# R7KA8M2AD register map
Vendor: Renesas Electronics Corporation; Series: RA8; File version: 1.10.02
CPU: CM85 r0p2, little endian, MPU, FPU, VTOR, 4 interrupt priority bits, 96 interrupts
Registers are 32-bit, read-write, reset 0x0 unless marked. A register's access mark holds for its fields unless they carry their own. Offsets are from the block's base; [hi:lo] are bit positions; {n}, {i} and the like mark numbered series; 'fields as' and 'values as' point back to an identical list.

## GWCA0 — Gateway CPU Agent
Base 0x403CE000
Same registers: GWCA0_NS 0x503CE000
0x00 GWMC reset 0x1 — Mode Configuration Register
  [1:0] OPC — Operating Mode Command
    0=Enter RESET mode; 1=Enter DISABLE mode; 2=Enter CONFIG mode; 3=Enter OPERATION mode
0x04 GWMS ro reset 0x1 — Mode Status Register
  [1:0] OPS — Operating Mode Status
    0=RESET mode; 1=DISABLE mode; 2=CONFIG mode; 3=OPERATION mode
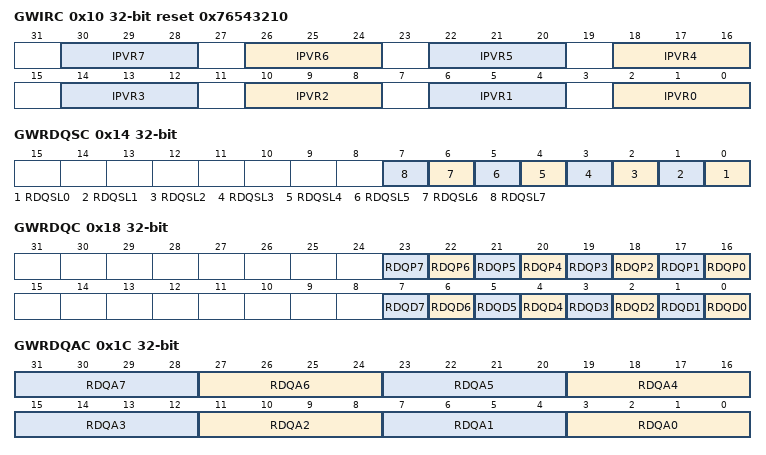
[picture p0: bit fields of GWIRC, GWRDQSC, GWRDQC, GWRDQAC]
0x10 GWIRC reset 0x76543210 — IPV Remapping Configuration Register [802.1Q]
  [4n+2:4n] IPVR{n} (n=0..7) — IPV remapping {n}
0x14 GWRDQSC — RX Descriptor Queue Security Configuration Register
  [all] fields
    0=Queue i unsecure; 1=Queue i secure
  [n] RDQSL{n} (n=0..7) — RX Descriptor Queue i Security Level (The variable i corresponds to the bit number.)
0x18 GWRDQC — RX Descriptor Queue Control Register
  [n+16] RDQP{n} (n=0..7) — RX Descriptor Queue i Pause (The variable i corresponds to the bit position number.)
    0=Queue i active; 1=Queue i paused
  [n] RDQD{n} (n=0..7) — RX Descriptor Queue i Disable (The variable i corresponds to the bit position number.)
    0=Queue i enabled; 1=Queue i disabled
0x1C GWRDQAC — RX Descriptor Queue Arbitration Control Register
  [all] fields
    0=Queue i strict arbitration; other=Others (Queue i WRR arbitration)
  [4n+3:4n] RDQA{n} (n=0..7) — RX Descriptor Queue {n} Arbitration
0x20 GWRGC — RX General Configuration Register
  [0] RCPT — Receive CRC Pass Through [802.3]
    0=FCS is not passed to GWCPU. If a descriptor is received from forwarding engine with FDESCR.FI equal to 1, GWCA remove the last 4 bytes of the Frame Data (FCS).; 1=FCS is passed to GWCPU GWCA don’t remove FCS from the Frame which has one (a descriptor is received from forwarding engine with FDESCR.FI equal to 1) if the frame has not been modified by the switch (No update due to VLAN tagging/untagging and no update requested by L3 routing [FWD])
{0x40+4i} GWRMFSC{i} (i=0..7) reset 0xFFFF — Reception Maximum Frame Size Configuration Register {i}
  [15:0] MFS — Maximum Frame Size
{0x60+4i} GWRDQDC{i} (i=0..7) — Reception Descriptor Queue {i} Depth Configuration Register
  [9:0] DQD — Descriptor Queue Depth
{0x80+4i} GWRDQM{i} (i=0..7) ro — RX Descriptor Queue {i} Monitoring Register
  [9:0] DNQ — Descriptor Number in Queue
{0xA0+4i} GWRDQMLM{i} (i=0..7) ro — RX Descriptor Queue {i} Max Level Monitoring Register
  [9:0] DMLQ — Descriptor Max Level in Queue
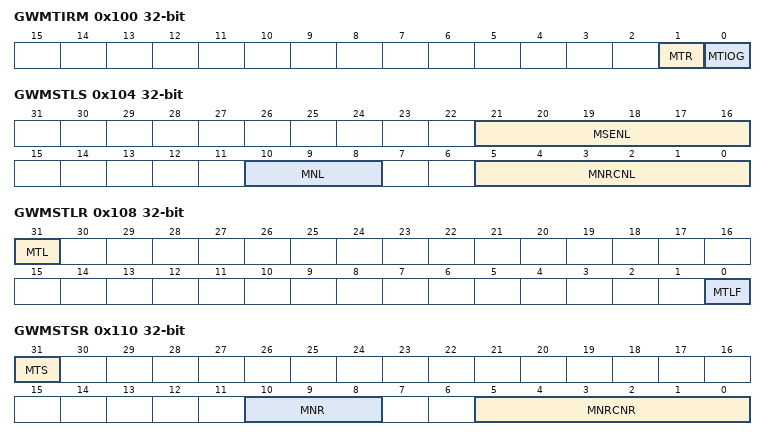
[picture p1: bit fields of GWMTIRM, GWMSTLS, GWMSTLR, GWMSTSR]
0x100 GWMTIRM — Multicast Table Initialization Register Monitoring Register
  [1] MTR ro — Multicast Table Ready
  [0] MTIOG — Multicast Table Initialization Ongoing
0x104 GWMSTLS — Multicast Table Learning Setting Register
  [21:16] MSENL — Multicast Setting Entry Number Learn
  [10:8] MNL — Multicast Number Learn
  [5:0] MNRCNL — Multicast Next Descriptor Chain Number Learn
0x108 GWMSTLR ro — Multicast Table Learning Result Register
  [31] MTL — Multicast Table Learning
  [0] MTLF — Multicast Table Learning Fail
    0=Entry learning did not fail because the Multicast table is not ready; 1=Entry learning failed the Multicast table is not ready
0x10C GWMSTSS — Multicast Table Searching Setting Register
  [5:0] MSENS — Multicast Setting Entry Number Search
0x110 GWMSTSR ro — Multicast Table Searching Result Register
  [31] MTS — Multicast Table Searching
  [10:8] MNR — Multicast Number Result
  [5:0] MNRCNR — Multicast Next RX Descriptor Chain Number Result
0x120 GWMAC0 — MAC Address Configuration Register 0
  [15:0] MAU — MAC Address Upper Part
0x124 GWMAC1 — MAC Address Configuration Register 1
  [31:0] MAL — MAC Address Lower Part
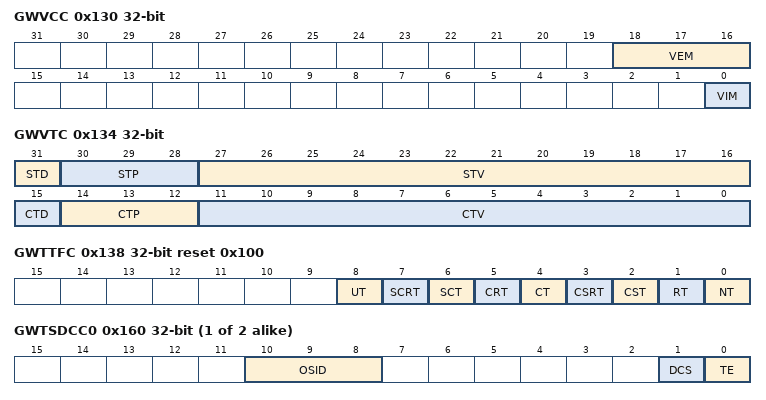
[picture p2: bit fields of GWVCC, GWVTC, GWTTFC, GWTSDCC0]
0x130 GWVCC — VLAN Control Configuration Register
  [18:16] VEM — VLAN Egress Mode
    0=No VLAN mode, frames are transmitted with no VLAN; 1=C-TAG VLAN mode, frames are transmitted with ingress C-TAG if there is one stored in the Local RAM; 2=HW C-TAG VLAN mode, frames are transmitted with the C-TAG stored in local RAM; 3=SC-TAG VLAN mode, frames are transmitted with ingress C-TAG and S-TAG if they were stored in the Local RAM; 4=HW SC-TAG VLAN mode, frames are transmitted with the C-TAG and S-TAG stored in local RAM
  [0] VIM — VLAN Ingress Mode
    0=Incoming VLAN mode; 1=Port based VLAN mode
0x134 GWVTC — VLAN TAG Configuration Register
  [31] STD — S-TAG DEI
  [30:28] STP — S-TAG PCP
  [27:16] STV — S-TAG VLAN
  [15] CTD — C-TAG DEI
  [14:12] CTP — C-TAG PCP
  [11:0] CTV — C-TAG VLAN
0x138 GWTTFC reset 0x100 — Transmission TAG Filtering Configuration Register
  [8] UT — Unknown TAG
    0=Unknown Tag frame passed; 1=Unknown Tag frame rejected
  [7] SCRT — SCR-TAG
    0=SCR-TAG frame passed; 1=SCR-TAG frame rejected
  [6] SCT — SC-TAG
    0=SC-TAG frame passed; 1=SC-TAG frame rejected
  [5] CRT — CR-TAG
    0=CR-TAG frame passed; 1=CR-TAG frame rejected
  [4] CT — C-TAG
    0=C-TAG frame passed; 1=C-TAG frame rejected
  [3] CSRT — CoSR-TAG
    0=CoSR-TAG frame passed; 1=CoSR-TAG frame rejected
  [2] CST — CoS-TAG
    0=CoS-TAG frame passed; 1=CoS-TAG frame rejected
  [1] RT — R-TAG
    0=R-TAG frame passed; 1=R-TAG frame rejected
  [0] NT — No Tag
    0=No Tag frame passed; 1=No Tag frame rejected
{0x140+8i} GWTDCAC{i}0 (i=0..1) — Timestamp Descriptor Chain {i} Address Configuration Register 0
  [7:0] TSCCAU — TS Descriptor Chain s Current Address Upper Part
{0x144+8i} GWTDCAC{i}1 (i=0..1) — Timestamp Descriptor Chain {i} Address Configuration Register 1
  [31:0] TSCCAL — TS Descriptor Chain s Current Address Lower Part
{0x160+4i} GWTSDCC{i} (i=0..1) — Timestamp Descriptor Chain {i} Configuration Register
  [10:8] OSID
  [1] DCS — Descriptor Chain Select
  [0] TE — Timer Enable
0x180 GWTSNM ro — Timestamp Number Monitoring Register
  [4:0] TNTR — Timestamp Number in Timestamp RAM
0x184 GWTSMNM ro — Timestamp Maximum Number Monitoring Register
  [4:0] TMNTR — Timestamp Maximum Number in Timestamp RAM
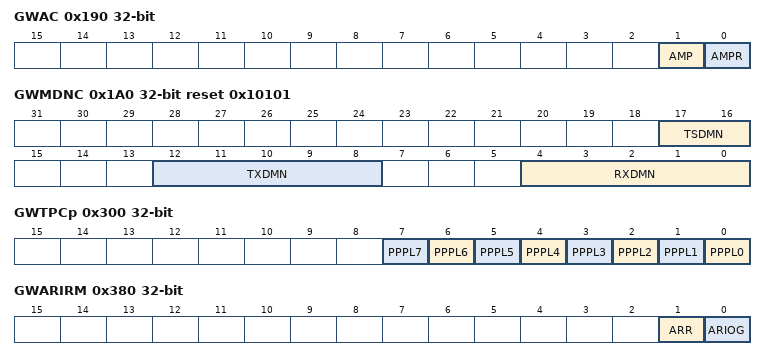
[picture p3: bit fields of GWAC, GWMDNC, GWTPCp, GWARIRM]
0x190 GWAC — AXI Control Register
  [1] AMP — AXI Master Paused
    0=AXI master not paused (transaction ongoing); 1=AXI master paused (no transaction ongoing)
  [0] AMPR — AXI Master Pause Request
    0=AXI master pause not requested; 1=AXI master pause requested
0x194 GWDCBAC0 — Descriptor Chain Base Address Configuration Register 0
  [7:0] DCBAU — Descriptor Chain Base Address Upper Part
0x198 GWDCBAC1 — Descriptor Chain Base Address Configuration Register 1
  [31:0] DCBAL — Descriptor Chain Base Address Lower Part
0x1A0 GWMDNC reset 0x10101 — Maximum Descriptor Number Configuration Register
  [17:16] TSDMN — Timestamp Descriptor Maximum Number
  [12:8] TXDMN — TX Descriptor Maximum Number
  [4:0] RXDMN — RX Descriptor Maximum Number
0x200 GWTRC0 — Transmission Request Configuration Register
0x204 GWTRC1 — Transmission Request Configuration Register
0x300 GWTPCp — Transmission Pause Configuration Register p (p = 0 to 1)
  [all] fields
    0=Transmission queues with their priority GWDCCi.DCP set to i are not paused when pause level p is set (PAUSE[2][p] is set [COMA]); 1=Transmission queues with the priority GWDCCi.DCP set to i are paused when pause level p is set (PAUSE[2][p] is set [COMA])
  [n] PPPL{n} (n=0..7) — Per Priority Pause Level i (The variable i corresponds to the bit position number.)
0x380 GWARIRM — AXI RAM Initialization Register Monitoring Register
  [1] ARR ro — AXI RAM Ready
  [0] ARIOG — AXI RAM Initialization Ongoing
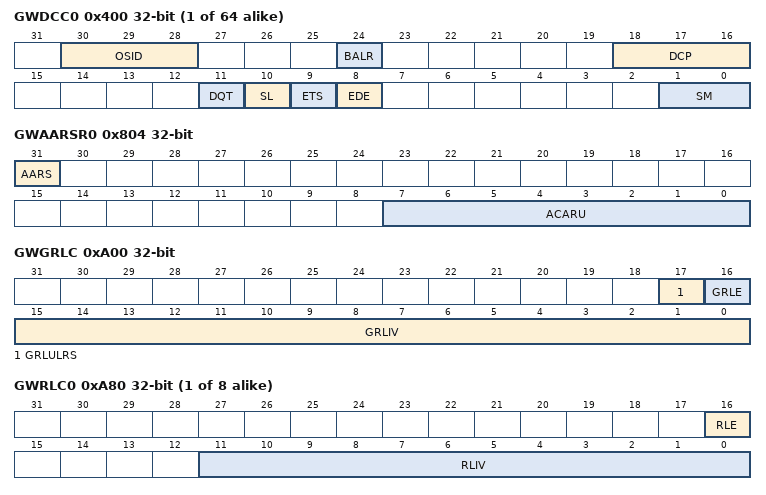
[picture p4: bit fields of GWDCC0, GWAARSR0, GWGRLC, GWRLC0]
{0x400+4i} GWDCC{i} (i=0..63) — Descriptor Chain {i} Configuration Register
  [30:28] OSID
  [24] BALR — Base Address Load Request
  [18:16] DCP — Descriptor Chain Priority
    0=Lowest priority; 7=Highest priority
  [11] DQT — Descriptor Queue Type
    0=Descriptor queue i is a reception queue; 1=Descriptor queue i is a transmission queue
  [10] SL — Security Level
    0=Chain i unsecure; 1=Chain i secure
  [9] ETS — Enable Timestamp Storage
    0=Timestamp is not added in the Descriptor; 1=Timestamp is added in the Descriptor
  [8] EDE — Extended Descriptor Enable
    0=Basic Descriptor; 1=Extended Descriptor
  [1:0] SM — Synchronization Mode
    0=Normal mode (full descriptor write back); 1=No-write-back mode (no descriptor write back); 2=Keep-DT mode (no update of DT field at descriptor write back)
0x800 GWAARSS — AXI Address RAM Searching Setting Register
  [5:0] AARA — AXI Address RAM Address
0x804 GWAARSR0 ro — AXI Address RAM Searching Result Register 0
  [31] AARS — AXI Address RAM Searching
  [7:0] ACARU — AXI Current Address Result Upper Part
0x808 GWAARSR1 ro — AXI Address RAM Searching Result Register 1
  [31:0] ACARL — AXI Current Address Result Lower Part
{0x840+4i} GWIDAUAS{i} (i=0..3) — Incremental Data Area {i} Used Area Size Register
  [23:0] IDAUAS — Incremental Data Area Used Size of RX Descriptor Chain i
{0x880+4i} GWIDASM{i} (i=0..3) ro — Incremental Data Area {i} Size Monitoring Register
  [23:0] IDAS — Incremental Data Area Size of RX Descriptor Chain i
{0x900+8i} GWIDASAM{i}0 (i=0..3) ro — Incremental Data Area {i} Start Address Monitoring Register 0
  [7:0] IDASAU — Incremental Data Area Start Address Upper Part of RX Descriptor Chain i
{0x904+8i} GWIDASAM{i}1 (i=0..3) ro — Incremental Data Area {i} Start Address Monitoring Register 1
  [31:0] IDASAL — Incremental Data Area Start Address Lower Part of RX Descriptor Chain i
{0x980+8i} GWIDACAM{i}0 (i=0..3) ro — Incremental Data Area {i} Current Address Monitoring Register 0
  [7:0] IDACAU — Incremental Data Area Current Address Upper Part of RX Descriptor Chain i
{0x984+8i} GWIDACAM{i}1 (i=0..3) ro — Incremental Data Area {i} Current Address Monitoring Register 1
  [31:0] IDACAL — Incremental Data Area Current Address Lower Part of RX Descriptor Chain i
0xA00 GWGRLC — Global Rate Limiter Configuration Register
  [17] GRLULRS — Global Rate Limiter Upper Limit Reached Status Flag
  [16] GRLE — Global Rate Limiter Enable
    0=Global Rate limiter disabled; 1=Global Rate limiter enabled
  [15:0] GRLIV — Global Rate Limiter Incremental Value
0xA04 GWGRLULC — Global Rate Limiter Upper Limit Configuration Register
  [23:0] GRLUL — Global Rate Limiter Upper Limit
{0xA80+8i} GWRLC{i} (i=0..7) — Rate Limiter {i} Configuration Register
  [16] RLE — Rate Limiter Enable
    0=Rate limiter i disabled; 1=Rate limiter i enabled
  [11:0] RLIV — Rate Limiter Incremental Value
{0xA84+8i} GWRLULC{i} (i=0..7) — Rate Limiter {i} Upper Limit Configuration Register
  [23:0] RLUL — Rate Limiter Upper Limit
0xB80 GWIDPC — Interrupt Delay Prescaler Configuration Register
  [9:0] IDPV — Interrupt Delay Prescaler Value
0x1000 GWRDCN ro — Received Data Counter Register
  [31:0] RDN — Received Data Number
0x1004 GWTDCN ro — Transmitted Data Counter Register
  [31:0] TDN — Transmitted Data Number
0x1008 GWTSCN ro — Timestamp Counter Register
  [31:0] TN — Timestamp Number
0x100C GWTSOVFECN ro — Timestamp Overflow Error Counter Register
  [15:0] TSOVFEN — Timestamp Overflow Error Number
0x1010 GWUSMFSECN ro — Under Minimum Frame Size Error Counter Register
  [15:0] USMFSEN — Under Switch Minimum Frame Size Error Number
0x1014 GWTFECN ro — TAG Filtering Error Counter Register
  [15:0] TFEN — TAG Filtering Error Number
0x1018 GWSEQECN ro — Sequence Error Counter Register
  [15:0] SEQEN — Sequence Error Number
0x1020 GWTXDNECN ro — TX Descriptor Number Error Counter Register
  [15:0] TXDNEN — TX Descriptor Number Error Number
0x1024 GWFSECN ro — Frame Size Error Counter Register
  [15:0] FSEN — Frame Size Error Number
0x1028 GWTDFECN ro — Timestamp Descriptor Full Error Counter Register
  [15:0] TDFEN — Timestamp Descriptor Full Error Number
0x102C GWTSDNECN ro — Timestamp Descriptor Number Error Counter Register
  [15:0] TSDNEN — Timestamp Descriptor Number Error Number
0x1030 GWDQOECN ro — Descriptor Queue Overflow Error Counter Register
  [15:0] DQOEN — Descriptor Queue Overflow Error Number
0x1034 GWDQSECN ro — Descriptor Queue Security Error Counter Register
  [15:0] DQSEN — Descriptor Queue Security Error Number
0x1038 GWDFECN ro — Descriptor Full Error Counter Register
  [15:0] DFEN — Descriptor Full Error Number
0x103C GWDSECN ro — Descriptor Security Error Counter Register
  [15:0] DSEN — Descriptor Security Error Number
0x1040 GWDSZECN ro — Data Size Error Counter Register
  [15:0] DSZEN — Data Size Error Number
0x1044 GWDCTECN ro — Descriptor Chain Type Error Counter Register
  [15:0] DCTEN — Descriptor Chain Type Error Number
0x1048 GWRXDNECN ro — RX Descriptor Number Error Counter Register
  [15:0] RXDNEN — RX Descriptor Number Error Number
0x1100 GWDIS0 — Data Interrupt Status Register
0x1104 GWDIE0 — Data Interrupt Enable Register
0x1108 GWDID0 — Data Interrupt Disable Register
0x110C GWDIDS0 — Data Interrupt Delayed Status Register
0x1110 GWDIS1 — Data Interrupt Status Register
0x1114 GWDIE1 — Data Interrupt Enable Register
0x1118 GWDID1 — Data Interrupt Disable Register
0x111C GWDIDS1 — Data Interrupt Delayed Status Register
0x1180 GWTSDIS — Timestamp Data Interrupt Status Register
  [1:0] TSDIS1 to TSDIS0 — Timestamp Data i Interrupt Status Flag
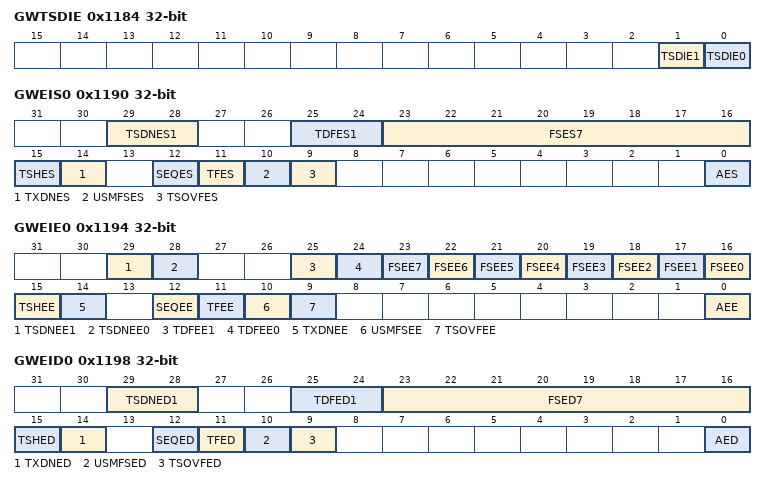
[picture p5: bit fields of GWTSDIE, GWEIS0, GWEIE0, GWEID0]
0x1184 GWTSDIE — Timestamp Data Interrupt Enable Register
  [1] TSDIE1 — Timestamp Data i Interrupt Enable
    0=Interrupt disabled; 1=Interrupt Enabled
  [0] TSDIE0 — Timestamp Data i Interrupt Enable
    0=Interrupt disabled; 1=Interrupt Enabled
0x1188 GWTSDID ro — Timestamp Data Interrupt Disable Register
  [1:0] TSDID1 to TSDID0 — Timestamp Data i Interrupt Disable
0x1190 GWEIS0 — Error Interrupt Status Register 0
  [29:28] TSDNES1 to TSDNES0 — Timestamp Descriptor i Number Error Status Flag
  [25:24] TDFES1 to TDFES0 — Timestamp Descriptor i Full Error Status Flag
  [23:16] FSES7 to FSES0 — Frame Size Error Status Flag i
  [15] TSHES — Timestamp Hardware Error Status Flag
  [14] TXDNES — TX Descriptor Number Error Status Flag
  [12] SEQES — Sequence Error Status Flag
  [11] TFES — TAG Filtering Error Status Flag
  [10] USMFSES — Under Switch Minimum Frame Size Error Status Flag
  [9] TSOVFES — Timestamp Overflow Error Status Flag
  [0] AES — AXI Error Status Flag
0x1194 GWEIE0 — Error Interrupt Enable Register 0
  [29] TSDNEE1 — Timestamp Descriptor i Number Error Enable
    0=Interrupt disabled; 1=Interrupt enabled
  [28] TSDNEE0 — Timestamp Descriptor i Number Error Enable
    0=Interrupt disabled; 1=Interrupt enabled
  [25] TDFEE1 — Timestamp Descriptor i Full Error Enable
    0=Interrupt disabled for descriptor queue i; 1=Interrupt enabled for descriptor queue i
  [24] TDFEE0 — Timestamp Descriptor i Full Error Enable
    values as TDFEE1
  [n+16] FSEE{n} (n=0..7) — Frame Size Error Enable i (The variable i corresponds to the bit position number.)
    0=Interrupt disabled for error q; 1=Interrupt enabled for error q
  [15] TSHEE — Timestamp Hardware Error Enable
    0=Interrupt disabled; 1=Interrupt Enabled
  [14] TXDNEE — TX Descriptor Number Error Enable
    0=Interrupt disabled; 1=Interrupt Enabled
  [12] SEQEE — Sequence Error Enable
    0=Interrupt disabled; 1=Interrupt Enabled
  [11] TFEE — TAG Filtering Error Enable
    0=Interrupt disabled; 1=Interrupt Enabled
  [10] USMFSEE — Under Minimum Frame Size Error Enable
    0=Interrupt disabled; 1=Interrupt Enabled
  [9] TSOVFEE — Timestamp Overflow Error Enable
    0=Interrupt disabled; 1=Interrupt Enabled
  [0] AEE — AXI Error Enable
    0=Interrupt disabled; 1=Interrupt Enabled
0x1198 GWEID0 ro — Error Interrupt Disable Register 0
  [29:28] TSDNED1 to TSDNED0 — Timestamp Descriptor i Number Error Disable
  [25:24] TDFED1 to TDFED0 — Timestamp Descriptor i Full Error Disable
  [23:16] FSED7 to FSED0 — Frame Size Error Disable i
  [15] TSHED — Timestamp Hardware Full Error Disable
  [14] TXDNED — TX Descriptor Number Error Disable
  [12] SEQED — Sequence Error Disable
  [11] TFED — TAG Filtering Error Disable
  [10] USMFSED — Under Minimum Frame Size Error Disable
  [9] TSOVFED — Timestamp Overflow Error Disable
  [0] AED — AXI Error Disable
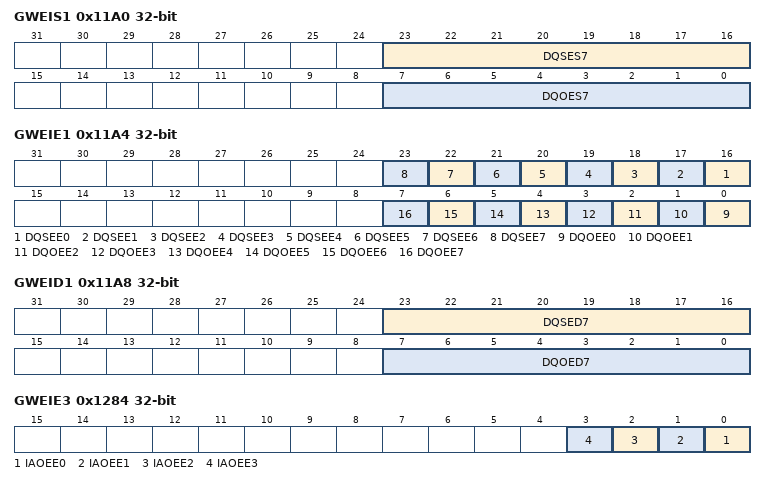
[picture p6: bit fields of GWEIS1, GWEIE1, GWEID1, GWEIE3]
0x11A0 GWEIS1 — Error Interrupt Status Register 1
  [23:16] DQSES7 to DQSES0 — Descriptor Queue i Security Error Status Flag (The variable i corresponds to the bit position number.)
  [7:0] DQOES7 to DQOES0 — Descriptor Queue i Overflow Error Status Flag
0x11A4 GWEIE1 — Error Interrupt Enable Register 1
  [all] fields
    values as GWEIE0.FSEE0
  [n+16] DQSEE{n} (n=0..7) — Descriptor Queue i Security Error Enable
  [n] DQOEE{n} (n=0..7) — Descriptor Queue i Overflow Error Enable
0x11A8 GWEID1 ro — Error Interrupt Disable Register 1
  [23:16] DQSED7 to DQSED0 — Descriptor Queue i Security Error Disable (The variable i corresponds to the bit position number.)
  [7:0] DQOED7 to DQOED0 — Descriptor Queue i Overflow Error Disable
0x1200 GWEIS20 — Error Interrupt Status Register 2
0x1204 GWEIE20 — Error Interrupt Enable Register 2
0x1208 GWEID20 — Error Interrupt Disable Register 2
0x1210 GWEIS21 — Error Interrupt Status Register 2
0x1214 GWEIE21 — Error Interrupt Enable Register 2
0x1218 GWEID21 — Error Interrupt Disable Register 2
0x1280 GWEIS3 — Error Interrupt Status Register 3
  [3:0] IAOES3 to IAOES0 — Incremental Area i Overflow Error Status Flag
0x1284 GWEIE3 — Error Interrupt Enable Register 3
  [all] fields
    0=Interrupt disabled; 1=Interrupt Enabled
  [n] IAOEE{n} (n=0..3) — Incremental Area i Overflow Error Enable
0x1288 GWEID3 ro — Error Interrupt Disable Register 3
  [3:0] IAOED3 to IAOED0 — Incremental Area i Overflow Error Disable
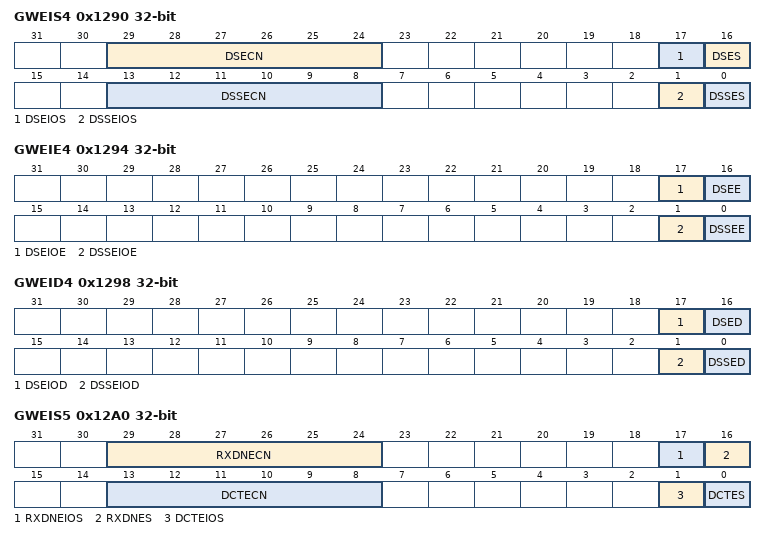
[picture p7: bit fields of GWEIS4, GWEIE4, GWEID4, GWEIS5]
0x1290 GWEIS4 — Error Interrupt Status Register 4
  [29:24] DSECN ro — Data Size Error Chain Number
  [17] DSEIOS — Data Size Error Interrupt Overflow Status Flag
  [16] DSES — Data Size Error Status Flag
  [13:8] DSSECN ro — Descriptor Security Error Chain Number
  [1] DSSEIOS — Descriptor Security Error Interrupt Overflow Status Flag
  [0] DSSES — Descriptor Security Error Status Flag
0x1294 GWEIE4 — Error Interrupt Enable Register 4
  [all] fields
    0=Interrupt disabled; 1=Interrupt Enabled
  [17] DSEIOE — Data Size Error Interrupt Overflow Interrupt Enable
  [16] DSEE — Data Size Error Enable
  [1] DSSEIOE — Descriptor Security Error Interrupt Overflow Enable
  [0] DSSEE — Descriptor Security Error Enable
0x1298 GWEID4 ro — Error Interrupt Disable Register 4
  [17] DSEIOD — Data Size Error Interrupt Overflow Disable
  [16] DSED — Data Size Error Disable
  [1] DSSEIOD — Descriptor Security Error Interrupt Overflow Disable
  [0] DSSED — Descriptor Security Error Disable
0x12A0 GWEIS5 — Error Interrupt Status Register 5
  [29:24] RXDNECN ro — RX Descriptor Number Error Chain Number
  [17] RXDNEIOS — RX Descriptor Number Error Interrupt Overflow Status Flag
  [16] RXDNES — RX Descriptor Number Error Status Flag
  [13:8] DCTECN ro — Descriptor Chain Type Error Chain Number
  [1] DCTEIOS — Descriptor Chain Type Error Interrupt Overflow Status Flag
  [0] DCTES — Descriptor Chain Type Error Status Flag
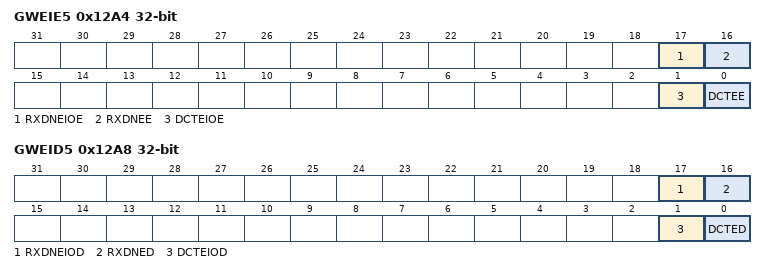
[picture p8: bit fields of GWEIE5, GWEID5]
0x12A4 GWEIE5 — Error Interrupt Enable Register 5
  [all] fields
    0=Interrupt disabled; 1=Interrupt Enabled
  [17] RXDNEIOE — RX Descriptor Number Error Interrupt Overflow Enable
  [16] RXDNEE — RX Descriptor Number Error Enable
  [1] DCTEIOE — Descriptor Chain Type Error Interrupt Overflow Enable
  [0] DCTEE — Descriptor Chain Type Error Enable
0x12A8 GWEID5 ro — Error Interrupt Disable Register 5
  [17] RXDNEIOD — RX Descriptor Number Error Interrupt Overflow Disable
  [16] RXDNED — RX Descriptor Number Error Disable
  [1] DCTEIOD — Descriptor Chain Type Error Interrupt Overflow Disable
  [0] DCTED — Descriptor Chain Type Error Disable
{0xC000+4i} GWIDC{i} (i=0..63) — Interrupt Delay {i} Configuration Register
  [11:0] IDV — Interrupt Delay Value
